# MK20D7 register map
File version: 1.6
Registers are 32-bit, access per field, reset 0x0 unless marked. A register's access mark holds for its fields unless they carry their own. Offsets are from the block's base; [hi:lo] are bit positions; lines under a group give offsets from that group; {n}, {i} and the like mark numbered series.

## FB — FlexBus external bus interface
Base 0x4000C000; register names take the prefix FB_
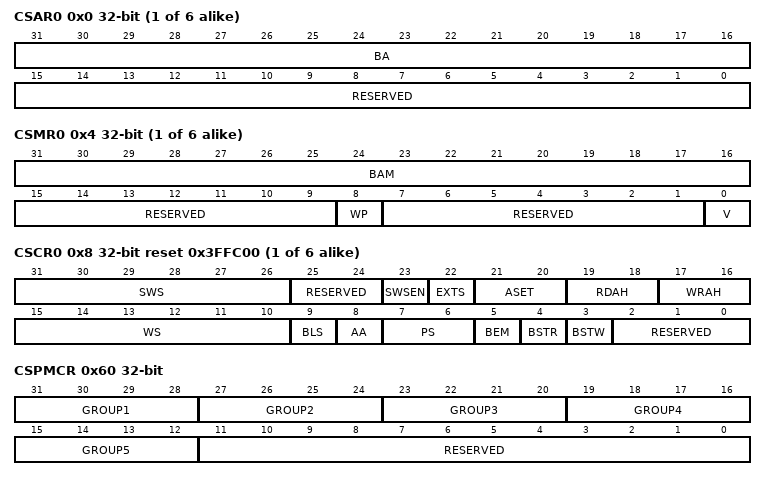
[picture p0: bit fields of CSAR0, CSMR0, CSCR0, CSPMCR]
{0x0+0xC*i} CSAR{i} (i=0..5) — Chip select address register
  [31:16] BA rw — Base address
  [15:0] RESERVED ro
{0x4+0xC*i} CSMR{i} (i=0..5) — Chip select mask register
  [31:16] BAM rw — Base address mask
    0=Corresponding address bit is used in chip-select decode; 1=Corresponding address bit is a don't care in chip-select decode
  [15:9] RESERVED ro
  [8] WP rw — Write protect
    0=Read and write accesses are allowed; 1=Only read accesses are allowed
  [7:1] RESERVED ro
  [0] V rw — Valid
    0=Chip select invalid; 1=Chip select valid
{0x8+0xC*i} CSCR{i} (i=0..5) reset 0x3FFC00 — Chip select control register
  [31:26] SWS rw — Secondary wait states
  [25:24] RESERVED ro
  [23] SWSEN rw — Secondary wait state enable
    0=The WS value inserts wait states before an internal transfer acknowledge is generated for all transfers; 1=The SWS value inserts wait states before an internal transfer acknowledge is generated for burst transfer secondary terminations
  [22] EXTS rw
    0=FB_TS /FB_ALE asserts for one bus clock cycle; 1=FB_TS /FB_ALE remains asserted until the first positive clock edge after FB_CSn asserts
  [21:20] ASET rw — Address setup
    0=Assert FB_CSn on first rising clock edge after address is asserted. (Default FB_CSn); 1=Assert FB_CSn on second rising clock edge after address is asserted; 2=Assert FB_CSn on third rising clock edge after address is asserted; 3=Assert FB_CSn on fourth rising clock edge after address is asserted. (Default FB_CS0)
  [19:18] RDAH rw — Read address hold or deselect
    0=If AA is cleared, 1 cycle. If AA is set, 0 cycles.; 1=If AA is cleared, 2 cycles. If AA is set, 1 cycle.; 2=If AA is cleared, 3 cycles. If AA is set, 2 cycles.; 3=If AA is cleared, 4 cycles. If AA is set, 3 cycles.
  [17:16] WRAH rw — Write address hold or deselect
    0=Hold address and attributes one cycle after FB_CSn negates on writes. (Default FB_CSn); 1=Hold address and attributes two cycles after FB_CSn negates on writes; 2=Hold address and attributes three cycles after FB_CSn negates on writes; 3=Hold address and attributes four cycles after FB_CSn negates on writes. (Default FB_CS0)
  [15:10] WS rw — Wait states
  [9] BLS rw — Byte-lane shift
    0=Not shifted. Data is left-justfied on FB_AD.; 1=Shifted. Data is right justified on FB_AD.
  [8] AA rw — Auto-acknowledge enable
    0=No internal FB_TA is asserted. Cycle is terminated externally; 1=Internal transfer acknowledge is asserted as specified by WS
  [7:6] PS rw — Port size
    0=32-bit port size. Valid data sampled and driven on FB_D[31:0]; 1=8-bit port size. Valid data sampled and driven on FB_D[31:24] if BLS = 0 or FB_D[7:0] if BLS = 1; 2=16-bit port size. Valid data sampled and driven on FB_D[31:16] if BLS = 0 or FB_D[15:0] if BLS = 1; 3=16-bit port size. Valid data sampled and driven on FB_D[31:16] if BLS = 0 or FB_D[15:0] if BLS = 1
  [5] BEM rw — Byte-enable mode
    0=The FB_BE n signals are not asserted for reads. The FB_BE n signals are asserted for data write only.; 1=The FB_BE n signals are asserted for read and write accesses
  [4] BSTR rw — Burst-read enable
    0=Data exceeding the specified port size is broken into individual, port-sized, non-burst reads. For example, a longword read from an 8-bit port is broken into four 8-bit reads.; 1=Enables data burst reads larger than the specified port size, including longword reads from 8- and 16-bit ports, word reads from 8-bit ports, and line reads from 8, 16-, and 32-bit ports
  [3] BSTW rw — Burst-write enable
    0=Break data larger than the specified port size into individual, port-sized, non-burst writes. For example, a longword write to an 8-bit port takes four byte writes.; 1=Enables burst write of data larger than the specified port size, including longword writes to 8 and 16-bit ports, word writes to 8-bit ports, and line writes to 8-, 16-, and 32-bit ports
  [2:0] RESERVED ro
0x60 CSPMCR — Chip select port multiplexing control register
  [31:28] GROUP1 rw — FlexBus signal group 1 multiplex control
    0=FB_ALE; 1=FB_CS1; 2=FB_TS
  [27:24] GROUP2 rw — FlexBus signal group 2 multiplex control
    0=FB_CS4; 1=FB_TSIZ0; 2=FB_BE_31_24
  [23:20] GROUP3 rw — FlexBus signal group 3 multiplex control
    0=FB_CS5; 1=FB_TSIZ1; 2=FB_BE_23_16
  [19:16] GROUP4 rw — FlexBus signal group 4 multiplex control
    0=FB_TBST; 1=FB_CS2; 2=FB_BE_15_8
  [15:12] GROUP5 rw — FlexBus signal group 5 multiplex control
    0=FB_TA; 1=FB_CS3. You must also set CSCRn[AA].; 2=FB_BE_7_0. You must also set CSCRn[AA].
  [11:0] RESERVED ro
